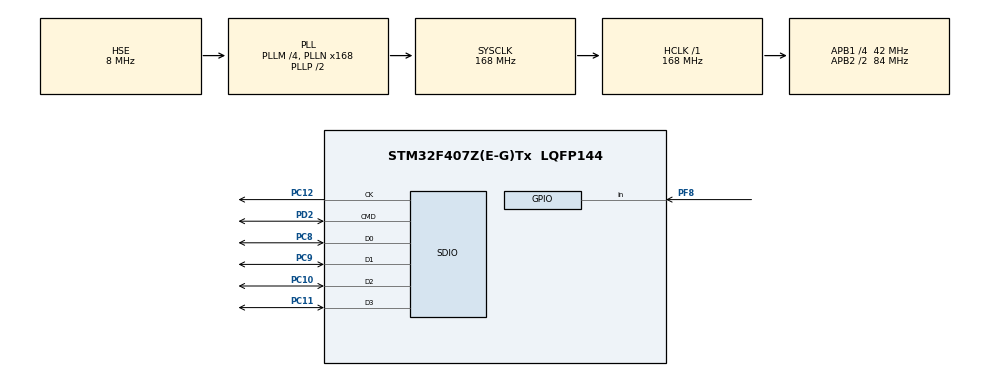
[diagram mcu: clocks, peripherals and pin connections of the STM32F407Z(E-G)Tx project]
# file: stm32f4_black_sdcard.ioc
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Dma.Request0=SDIO_RX
Dma.Request1=SDIO_TX
Dma.SDIO_RX.0.Direction=DMA_PERIPH_TO_MEMORY
Dma.SDIO_RX.0.FIFOMode=DMA_FIFOMODE_ENABLE
Dma.SDIO_RX.0.FIFOThreshold=DMA_FIFO_THRESHOLD_FULL
Dma.SDIO_RX.0.Instance=DMA2_Stream3
Dma.SDIO_RX.0.MemBurst=DMA_MBURST_INC4
Dma.SDIO_RX.0.MemDataAlignment=DMA_MDATAALIGN_WORD
Dma.SDIO_RX.0.MemInc=DMA_MINC_ENABLE
Dma.SDIO_RX.0.Mode=DMA_PFCTRL
Dma.SDIO_RX.0.PeriphBurst=DMA_PBURST_INC4
Dma.SDIO_RX.0.PeriphDataAlignment=DMA_PDATAALIGN_WORD
Dma.SDIO_RX.0.PeriphInc=DMA_PINC_DISABLE
Dma.SDIO_RX.0.Priority=DMA_PRIORITY_LOW
Dma.SDIO_TX.1.Direction=DMA_MEMORY_TO_PERIPH
Dma.SDIO_TX.1.FIFOMode=DMA_FIFOMODE_ENABLE
Dma.SDIO_TX.1.FIFOThreshold=DMA_FIFO_THRESHOLD_FULL
Dma.SDIO_TX.1.Instance=DMA2_Stream6
Dma.SDIO_TX.1.MemBurst=DMA_MBURST_INC4
Dma.SDIO_TX.1.MemDataAlignment=DMA_MDATAALIGN_WORD
Dma.SDIO_TX.1.MemInc=DMA_MINC_ENABLE
Dma.SDIO_TX.1.Mode=DMA_PFCTRL
Dma.SDIO_TX.1.PeriphBurst=DMA_PBURST_INC4
Dma.SDIO_TX.1.PeriphDataAlignment=DMA_PDATAALIGN_WORD
Dma.SDIO_TX.1.PeriphInc=DMA_PINC_DISABLE
Dma.SDIO_TX.1.Priority=DMA_PRIORITY_LOW
FATFS.BSP.number=1
FATFS.USE_DMA_CODE_SD=1
FATFS._MAX_SS=4096
FATFS._USE_LFN=2
FATFS0.BSP.STBoard=false
FATFS0.BSP.api=Unknown
FATFS0.BSP.i2caddr=0
FATFS0.BSP.instance=PF8
FATFS0.BSP.ip=GPIO
FATFS0.BSP.mode=Input
FATFS0.BSP.name=Detect_SDIO
FATFS0.BSP.solution=PF8
Mcu.Family=STM32F4
Mcu.Name=STM32F407Z(E-G)Tx
Mcu.Package=LQFP144
NVIC.DMA2_Stream3_IRQn=true\:0\:0\:false\:false\:true\:false\:true
NVIC.DMA2_Stream6_IRQn=true\:0\:0\:false\:false\:true\:false\:true
NVIC.PriorityGroup=NVIC_PRIORITYGROUP_4
NVIC.SDIO_IRQn=true\:0\:0\:false\:false\:true\:true\:true
PC10.GPIO_PuPd=GPIO_NOPULL
PC10.Mode=SD_4_bits_Wide_bus
PC10.Signal=SDIO_D2
PC11.GPIO_PuPd=GPIO_NOPULL
PC11.Mode=SD_4_bits_Wide_bus
PC11.Signal=SDIO_D3
PC12.Mode=SD_4_bits_Wide_bus
PC12.Signal=SDIO_CK
PC8.GPIO_PuPd=GPIO_NOPULL
PC8.Mode=SD_4_bits_Wide_bus
PC8.Signal=SDIO_D0
PC9.GPIO_PuPd=GPIO_NOPULL
PC9.Mode=SD_4_bits_Wide_bus
PC9.Signal=SDIO_D1
PD2.GPIO_PuPd=GPIO_NOPULL
PD2.Mode=SD_4_bits_Wide_bus
PD2.Signal=SDIO_CMD
PF8.Signal=GPIO_Input
PH0-OSC_IN.Mode=HSE-External-Oscillator
PH0-OSC_IN.Signal=RCC_OSC_IN
PH1-OSC_OUT.Mode=HSE-External-Oscillator
PH1-OSC_OUT.Signal=RCC_OSC_OUT
ProjectManager.HeapSize=0x200
ProjectManager.StackSize=0x400
ProjectManager.TargetToolchain=STM32CubeIDE
RCC.48MHZClocksFreq_Value=48000000
RCC.AHBFreq_Value=168000000
RCC.APB1CLKDivider=RCC_HCLK_DIV4
RCC.APB1Freq_Value=42000000
RCC.APB1TimFreq_Value=84000000
RCC.APB2CLKDivider=RCC_HCLK_DIV2
RCC.APB2Freq_Value=84000000
RCC.APB2TimFreq_Value=168000000
RCC.CortexFreq_Value=168000000
RCC.EnbaleCSS=true
RCC.HCLKFreq_Value=168000000
RCC.HSE_VALUE=8000000
RCC.HSI_VALUE=16000000
RCC.LSE_VALUE=32768
RCC.PLLM=4
RCC.PLLN=168
RCC.PLLQ=7
RCC.PLLSourceVirtual=RCC_PLLSOURCE_HSE
RCC.SYSCLKFreq_VALUE=168000000
RCC.SYSCLKSource=RCC_SYSCLKSOURCE_PLLCLK
RCC.VCOOutputFreq_Value=336000000
SDIO.ClockBypass=SDIO_CLOCK_BYPASS_ENABLE
SDIO.ClockDiv=0
VP_FATFS_VS_SDIO.Mode=SDIO
board=custom

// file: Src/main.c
/* USER CODE BEGIN Header */
/**
  ******************************************************************************
  * @file           : main.c
  * @brief          : Main program body
  ******************************************************************************
  * @attention
  *
  * <h2><center>&copy; Copyright (c) 2019 STMicroelectronics.
  * All rights reserved.</center></h2>
  *
  * This software component is licensed by ST under BSD 3-Clause license,
  * the "License"; You may not use this file except in compliance with the
  * License. You may obtain a copy of the License at:
  *                        opensource.org/licenses/BSD-3-Clause
  *
  ******************************************************************************
  */
/* USER CODE END Header */

#include "main.h"
#include "fatfs.h"

SD_HandleTypeDef hsd;
DMA_HandleTypeDef hdma_sdio_rx;
DMA_HandleTypeDef hdma_sdio_tx;

void SystemClock_Config(void);
static void MX_GPIO_Init(void);
static void MX_DMA_Init(void);
static void MX_SDIO_SD_Init(void);

int main(void)
{

  /* MCU Configuration--------------------------------------------------------*/

  /* Reset of all peripherals, Initializes the Flash interface and the Systick. */
  HAL_Init();

  /* Configure the system clock */
  SystemClock_Config();

  /* Initialize all configured peripherals */
  MX_GPIO_Init();
  MX_DMA_Init();
  MX_SDIO_SD_Init();
  MX_FATFS_Init();
  /* USER CODE BEGIN 2 */

  FATFS fileSystem;
  FIL testFile;
  uint8_t testBuffer[16] = "SD write success";
  UINT testBytes;
  FRESULT res;
  res = f_mount(&fileSystem, SDPath, 1);
  if(res == FR_OK)
  {
    uint8_t path[13] = "testfile.txt";
    path[12] = '\0';

    res = f_open(&testFile, (char*)path, FA_WRITE | FA_CREATE_ALWAYS);

    res = f_write(&testFile, testBuffer, 16, &testBytes);

    res = f_close(&testFile);
  }

  /* USER CODE END 2 */

  /* Infinite loop */
  while (1)
  {

  }
}

void SystemClock_Config(void)
{
  RCC_OscInitTypeDef RCC_OscInitStruct = {0};
  RCC_ClkInitTypeDef RCC_ClkInitStruct = {0};

  /** Configure the main internal regulator output voltage
  */
  __HAL_RCC_PWR_CLK_ENABLE();
  __HAL_PWR_VOLTAGESCALING_CONFIG(PWR_REGULATOR_VOLTAGE_SCALE1);
  /** Initializes the CPU, AHB and APB busses clocks
  */
  RCC_OscInitStruct.OscillatorType = RCC_OSCILLATORTYPE_HSE;
  RCC_OscInitStruct.HSEState = RCC_HSE_ON;
  RCC_OscInitStruct.PLL.PLLState = RCC_PLL_ON;
  RCC_OscInitStruct.PLL.PLLSource = RCC_PLLSOURCE_HSE;
  RCC_OscInitStruct.PLL.PLLM = 4;
  RCC_OscInitStruct.PLL.PLLN = 168;
  RCC_OscInitStruct.PLL.PLLP = RCC_PLLP_DIV2;
  RCC_OscInitStruct.PLL.PLLQ = 7;
  if (HAL_RCC_OscConfig(&RCC_OscInitStruct) != HAL_OK)
  {
    Error_Handler();
  }
  /** Initializes the CPU, AHB and APB busses clocks
  */
  RCC_ClkInitStruct.ClockType = RCC_CLOCKTYPE_HCLK|RCC_CLOCKTYPE_SYSCLK
                              |RCC_CLOCKTYPE_PCLK1|RCC_CLOCKTYPE_PCLK2;
  RCC_ClkInitStruct.SYSCLKSource = RCC_SYSCLKSOURCE_PLLCLK;
  RCC_ClkInitStruct.AHBCLKDivider = RCC_SYSCLK_DIV1;
  RCC_ClkInitStruct.APB1CLKDivider = RCC_HCLK_DIV4;
  RCC_ClkInitStruct.APB2CLKDivider = RCC_HCLK_DIV2;

  if (HAL_RCC_ClockConfig(&RCC_ClkInitStruct, FLASH_LATENCY_5) != HAL_OK)
  {
    Error_Handler();
  }
  /** Enables the Clock Security System
  */
  HAL_RCC_EnableCSS();
}

static void MX_SDIO_SD_Init(void)
{

  hsd.Instance = SDIO;
  hsd.Init.ClockEdge = SDIO_CLOCK_EDGE_RISING;
  hsd.Init.ClockBypass = SDIO_CLOCK_BYPASS_ENABLE;
  hsd.Init.ClockPowerSave = SDIO_CLOCK_POWER_SAVE_DISABLE;
  hsd.Init.BusWide = SDIO_BUS_WIDE_1B;
  hsd.Init.HardwareFlowControl = SDIO_HARDWARE_FLOW_CONTROL_DISABLE;
  hsd.Init.ClockDiv = 0;

}

static void MX_DMA_Init(void)
{

  /* DMA controller clock enable */
  __HAL_RCC_DMA2_CLK_ENABLE();

  /* DMA interrupt init */
  /* DMA2_Stream3_IRQn interrupt configuration */
  HAL_NVIC_SetPriority(DMA2_Stream3_IRQn, 0, 0);
  HAL_NVIC_EnableIRQ(DMA2_Stream3_IRQn);
  /* DMA2_Stream6_IRQn interrupt configuration */
  HAL_NVIC_SetPriority(DMA2_Stream6_IRQn, 0, 0);
  HAL_NVIC_EnableIRQ(DMA2_Stream6_IRQn);

}

static void MX_GPIO_Init(void)
{
  GPIO_InitTypeDef GPIO_InitStruct = {0};

  /* GPIO Ports Clock Enable */
  __HAL_RCC_GPIOF_CLK_ENABLE();
  __HAL_RCC_GPIOH_CLK_ENABLE();
  __HAL_RCC_GPIOC_CLK_ENABLE();
  __HAL_RCC_GPIOD_CLK_ENABLE();

  /*Configure GPIO pin : PF8 */
  GPIO_InitStruct.Pin = GPIO_PIN_8;
  GPIO_InitStruct.Mode = GPIO_MODE_INPUT;
  GPIO_InitStruct.Pull = GPIO_NOPULL;
  HAL_GPIO_Init(GPIOF, &GPIO_InitStruct);

}

void Error_Handler(void)
{
}

/************************ (C) COPYRIGHT STMicroelectronics *****END OF FILE****/
